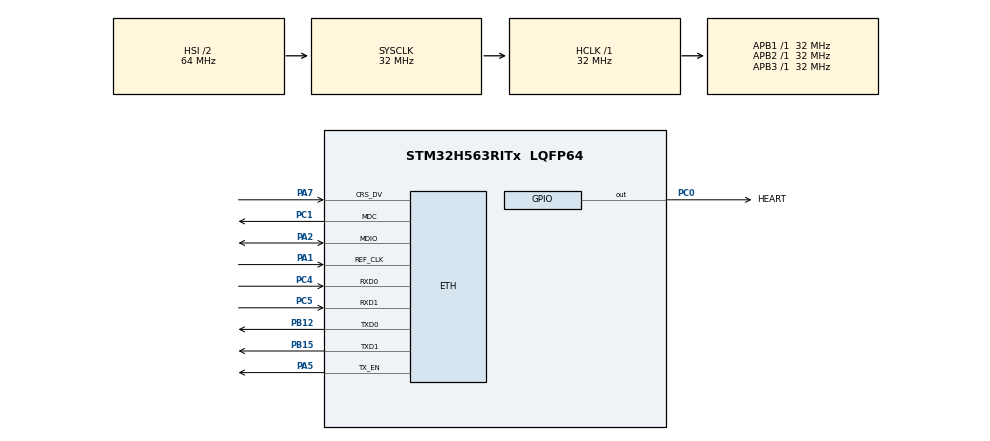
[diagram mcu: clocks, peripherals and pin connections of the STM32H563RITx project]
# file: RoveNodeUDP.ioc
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CORTEX_M33_NS.Number-Cortex_Memory_Protection_Unit_Region0_OTP_RO_AREAS_Settings=MPU_REGION_NUMBER0
CORTEX_M33_NS.default_mode_Activation=1
CORTEX_M33_NS.userName=CORTEX_M33
ETH.MediaInterface=HAL_ETH_RMII_MODE
Mcu.Family=STM32H5
Mcu.Name=STM32H563RITx
Mcu.Package=LQFP64
NVIC.ETH_IRQn=true\:0\:0\:false\:false\:true\:true\:true\:true
NVIC.PriorityGroup=NVIC_PRIORITYGROUP_4
PA1.Mode=RMII
PA1.Signal=ETH_REF_CLK
PA13(JTMS/SWDIO).Mode=Serial_Wire
PA13(JTMS/SWDIO).Signal=DEBUG_JTMS-SWDIO
PA14(JTCK/SWCLK).Mode=Serial_Wire
PA14(JTCK/SWCLK).Signal=DEBUG_JTCK-SWCLK
PA2.Mode=RMII
PA2.Signal=ETH_MDIO
PA5.Mode=RMII
PA5.Signal=ETH_TX_EN
PA7.Mode=RMII
PA7.Signal=ETH_CRS_DV
PB12.Mode=RMII
PB12.Signal=ETH_TXD0
PB15.Mode=RMII
PB15.Signal=ETH_TXD1
PC0.GPIO_Label=HEART
PC0.Signal=GPIO_Output
PC1.Mode=RMII
PC1.Signal=ETH_MDC
PC4.Mode=RMII
PC4.Signal=ETH_RXD0
PC5.Mode=RMII
PC5.Signal=ETH_RXD1
ProjectManager.HeapSize=0x200
ProjectManager.StackSize=0x400
ProjectManager.TargetToolchain=STM32CubeIDE
RCC.ADCFreq_Value=32000000
RCC.AHBFreq_Value=32000000
RCC.APB1Freq_Value=32000000
RCC.APB1TimFreq_Value=32000000
RCC.APB2Freq_Value=32000000
RCC.APB2TimFreq_Value=32000000
RCC.APB3Freq_Value=32000000
RCC.CSI_VALUE=4000000
RCC.CortexFreq_Value=32000000
RCC.EPOD_VALUE=4000000
RCC.HCLKFreq_Value=32000000
RCC.HSE_VALUE=25000000
RCC.HSI48_VALUE=48000000
RCC.HSI_VALUE=64000000
RCC.LSE_VALUE=32768
RCC.LSIRC_VALUE=32000
RCC.PLLFRACN=0
RCC.PLLN=32
RCC.SYSCLKFreq_VALUE=32000000
RCC.USBFreq_Value=48000000
RCC.VCOOutputFreq_Value=128000000
VP_BOOTPATH_VS_BOOTPATH.Mode=BP_Activate
VP_CORTEX_M33_NS_VS_Hclk.Mode=Hclk_Mode
VP_ICACHE_VS_ICACHE.Mode=DirectMappedCache
VP_MEMORYMAP_VS_MEMORYMAP.Mode=CurAppReg
VP_PWR_VS_LPOM.Mode=PowerOptimisation
VP_PWR_VS_SECSignals.Mode=Security/Privilege
board=custom

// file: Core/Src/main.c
/* USER CODE BEGIN Header */
/**
  ******************************************************************************
  * @file           : main.c
  * @brief          : Main program body
  ******************************************************************************
  * @attention
  *
  * Copyright (c) 2026 STMicroelectronics.
  * All rights reserved.
  *
  * This software is licensed under terms that can be found in the LICENSE file
  * in the root directory of this software component.
  * If no LICENSE file comes with this software, it is provided AS-IS.
  *
  ******************************************************************************
  */
/* USER CODE END Header */
#include "main.h"
#include "string.h"

ETH_TxPacketConfigTypeDef TxConfig;
ETH_DMADescTypeDef  DMARxDscrTab[ETH_RX_DESC_CNT]; /* Ethernet Rx DMA Descriptors */
ETH_DMADescTypeDef  DMATxDscrTab[ETH_TX_DESC_CNT]; /* Ethernet Tx DMA Descriptors */

ETH_HandleTypeDef heth;

/* USER CODE BEGIN PV */
struct netif gnetif;

void udp_receive_callback(void *arg, struct udp_pcb *upcb, struct pbuf *p, const ip_addr_t *addr, u16_t port);
static void udpClient_send(const char *message);

struct udp_pcb *upcb;
char buffer[100];
/* USER CODE END PV */

void SystemClock_Config(void);
static void MPU_Config(void);
static void MX_GPIO_Init(void);
static void MX_ETH_Init(void);
static void MX_ICACHE_Init(void);

/* USER CODE BEGIN 0 */
static void udpClient_send(const char *message)
{
    struct pbuf *txBuf;
    int len = strlen(message);

    /* Allocate pbuf from pool */
    txBuf = pbuf_alloc(PBUF_TRANSPORT, len, PBUF_RAM);

    if (txBuf != NULL)
    {
        /* Copy data to pbuf */
        pbuf_take(txBuf, message, len);

        /* Send UDP data */
        udp_send(upcb, txBuf);

        /* Free pbuf */
        pbuf_free(txBuf);
    }
}

void udp_receive_callback(void *arg, struct udp_pcb *upcb, struct pbuf *p, const ip_addr_t *addr, u16_t port)
{
	if (p != NULL)
	    {
	        /* Safely copy data into 'buffer' up to its maximum size (minus 1 for null terminator) */
	        uint16_t copy_len = (p->tot_len < (sizeof(buffer) - 1)) ? p->tot_len : (sizeof(buffer) - 1);
	        pbuf_copy_partial(p, buffer, copy_len, 0);
	        buffer[copy_len] = '\0'; // Ensure null termination

	        HAL_GPIO_TogglePin(GPIOB, GPIO_PIN_0);

	        /* Free receive pbuf */
	        pbuf_free(p);
	    }
}
/* USER CODE END 0 */

int main(void)
{

  /* MCU Configuration--------------------------------------------------------*/

  /* MPU Configuration--------------------------------------------------------*/
  MPU_Config();

  /* Reset of all peripherals, Initializes the Flash interface and the Systick. */
  HAL_Init();

  /* Configure the system clock */
  SystemClock_Config();

  /* Initialize all configured peripherals */
  MX_GPIO_Init();
  MX_ETH_Init();
  MX_ICACHE_Init();
  /* USER CODE BEGIN 2 */
  HAL_ETH_Start(&heth);
  //SCB_DisableDCache();
  //SCB_DisableICache();

  err_t err;

  /* 1. Create a new UDP control block  */
  upcb = udp_new();

  /* Bind the block to module's IP and port */
  ip_addr_t myIPaddr;
  IP_ADDR4(&myIPaddr, 192, 168, 8, 200);
  udp_bind(upcb, &myIPaddr, 1100);

  /* Configure destination IP address and port */
  ip_addr_t DestIPaddr;
  IP_ADDR4(&DestIPaddr, 192, 168, 8, 108);
  err = udp_connect(upcb, &DestIPaddr, 1234);

  HAL_GPIO_WritePin(GPIOB, GPIO_PIN_0, 1);
  if (err == ERR_OK)
  {
	  /* 2. Send "Hello World" message to server */
	  udpClient_send("Hello World");

	  /* 3. Set a receive callback for the upcb */
	  udp_recv(upcb, udp_receive_callback, NULL);
  }

  /* USER CODE END 2 */

  /* Infinite loop */
  /* USER CODE BEGIN WHILE */
  while (1)
  {
	ethernetif_input(&gnetif);
	sys_check_timeouts();

	//udpClient_send("Hello World");
    /* USER CODE END WHILE */

  }
}

void SystemClock_Config(void)
{
  RCC_OscInitTypeDef RCC_OscInitStruct = {0};
  RCC_ClkInitTypeDef RCC_ClkInitStruct = {0};

  /** Configure the main internal regulator output voltage
  */
  __HAL_PWR_VOLTAGESCALING_CONFIG(PWR_REGULATOR_VOLTAGE_SCALE3);

  while(!__HAL_PWR_GET_FLAG(PWR_FLAG_VOSRDY)) {}

  /** Initializes the RCC Oscillators according to the specified parameters
  * in the RCC_OscInitTypeDef structure.
  */
  RCC_OscInitStruct.OscillatorType = RCC_OSCILLATORTYPE_HSI|RCC_OSCILLATORTYPE_CSI;
  RCC_OscInitStruct.HSIState = RCC_HSI_ON;
  RCC_OscInitStruct.HSIDiv = RCC_HSI_DIV2;
  RCC_OscInitStruct.HSICalibrationValue = RCC_HSICALIBRATION_DEFAULT;
  RCC_OscInitStruct.CSIState = RCC_CSI_ON;
  RCC_OscInitStruct.CSICalibrationValue = RCC_CSICALIBRATION_DEFAULT;
  RCC_OscInitStruct.PLL.PLLState = RCC_PLL_ON;
  RCC_OscInitStruct.PLL.PLLSource = RCC_PLL1_SOURCE_CSI;
  RCC_OscInitStruct.PLL.PLLM = 1;
  RCC_OscInitStruct.PLL.PLLN = 129;
  RCC_OscInitStruct.PLL.PLLP = 2;
  RCC_OscInitStruct.PLL.PLLQ = 2;
  RCC_OscInitStruct.PLL.PLLR = 2;
  RCC_OscInitStruct.PLL.PLLRGE = RCC_PLL1_VCIRANGE_2;
  RCC_OscInitStruct.PLL.PLLVCOSEL = RCC_PLL1_VCORANGE_WIDE;
  RCC_OscInitStruct.PLL.PLLFRACN = 0;
  if (HAL_RCC_OscConfig(&RCC_OscInitStruct) != HAL_OK)
  {
    Error_Handler();
  }

  /** Initializes the CPU, AHB and APB buses clocks
  */
  RCC_ClkInitStruct.ClockType = RCC_CLOCKTYPE_HCLK|RCC_CLOCKTYPE_SYSCLK
                              |RCC_CLOCKTYPE_PCLK1|RCC_CLOCKTYPE_PCLK2
                              |RCC_CLOCKTYPE_PCLK3;
  RCC_ClkInitStruct.SYSCLKSource = RCC_SYSCLKSOURCE_HSI;
  RCC_ClkInitStruct.AHBCLKDivider = RCC_SYSCLK_DIV1;
  RCC_ClkInitStruct.APB1CLKDivider = RCC_HCLK_DIV1;
  RCC_ClkInitStruct.APB2CLKDivider = RCC_HCLK_DIV1;
  RCC_ClkInitStruct.APB3CLKDivider = RCC_HCLK_DIV1;

  if (HAL_RCC_ClockConfig(&RCC_ClkInitStruct, FLASH_LATENCY_1) != HAL_OK)
  {
    Error_Handler();
  }

  /** Configure the programming delay
  */
  __HAL_FLASH_SET_PROGRAM_DELAY(FLASH_PROGRAMMING_DELAY_0);
}

static void MX_ETH_Init(void)
{

   static uint8_t MACAddr[6];

  heth.Instance = ETH;
  MACAddr[0] = 0x00;
  MACAddr[1] = 0x80;
  MACAddr[2] = 0xE1;
  MACAddr[3] = 0x00;
  MACAddr[4] = 0x00;
  MACAddr[5] = 0x00;
  heth.Init.MACAddr = &MACAddr[0];
  heth.Init.MediaInterface = HAL_ETH_RMII_MODE;
  heth.Init.TxDesc = DMATxDscrTab;
  heth.Init.RxDesc = DMARxDscrTab;
  heth.Init.RxBuffLen = 1524;

  if (HAL_ETH_Init(&heth) != HAL_OK)
  {
    Error_Handler();
  }

  memset(&TxConfig, 0 , sizeof(ETH_TxPacketConfigTypeDef));
  TxConfig.Attributes = ETH_TX_PACKETS_FEATURES_CSUM | ETH_TX_PACKETS_FEATURES_CRCPAD;
  TxConfig.ChecksumCtrl = ETH_CHECKSUM_IPHDR_PAYLOAD_INSERT_PHDR_CALC;
  TxConfig.CRCPadCtrl = ETH_CRC_PAD_INSERT;

}

static void MX_ICACHE_Init(void)
{

  /** Enable instruction cache in 1-way (direct mapped cache)
  */
  if (HAL_ICACHE_ConfigAssociativityMode(ICACHE_1WAY) != HAL_OK)
  {
    Error_Handler();
  }
  if (HAL_ICACHE_Enable() != HAL_OK)
  {
    Error_Handler();
  }

}

static void MX_GPIO_Init(void)
{
  GPIO_InitTypeDef GPIO_InitStruct = {0};

  /* GPIO Ports Clock Enable */
  __HAL_RCC_GPIOC_CLK_ENABLE();
  __HAL_RCC_GPIOA_CLK_ENABLE();
  __HAL_RCC_GPIOB_CLK_ENABLE();

  /*Configure GPIO pin Output Level */
  HAL_GPIO_WritePin(GPIOB, GPIO_PIN_0, GPIO_PIN_RESET);

  /*Configure GPIO pin : PB0 */
  GPIO_InitStruct.Pin = GPIO_PIN_0;
  GPIO_InitStruct.Mode = GPIO_MODE_OUTPUT_PP;
  GPIO_InitStruct.Pull = GPIO_NOPULL;
  GPIO_InitStruct.Speed = GPIO_SPEED_FREQ_LOW;
  HAL_GPIO_Init(GPIOB, &GPIO_InitStruct);

}

 /* MPU Configuration */

void MPU_Config(void)
{
  MPU_Region_InitTypeDef MPU_InitStruct = {0};
  MPU_Attributes_InitTypeDef MPU_AttributesInit = {0};

  /* Disables the MPU */
  HAL_MPU_Disable();

  /** Initializes and configures the Region 0 and the memory to be protected
  */
  MPU_InitStruct.Enable = MPU_REGION_ENABLE;
  MPU_InitStruct.Number = MPU_REGION_NUMBER0;
  MPU_InitStruct.BaseAddress = 0x08FFF000;
  MPU_InitStruct.LimitAddress = 0x08FFFFFF;
  MPU_InitStruct.AttributesIndex = MPU_ATTRIBUTES_NUMBER0;
  MPU_InitStruct.AccessPermission = MPU_REGION_ALL_RO;
  MPU_InitStruct.DisableExec = MPU_INSTRUCTION_ACCESS_DISABLE;
  MPU_InitStruct.IsShareable = MPU_ACCESS_NOT_SHAREABLE;

  HAL_MPU_ConfigRegion(&MPU_InitStruct);

  /** Initializes and configures the Attribute 0 and the memory to be protected
  */
  MPU_AttributesInit.Number = MPU_ATTRIBUTES_NUMBER0;
  MPU_AttributesInit.Attributes = INNER_OUTER(MPU_NOT_CACHEABLE);

  HAL_MPU_ConfigMemoryAttributes(&MPU_AttributesInit);
  /* Enables the MPU */
  HAL_MPU_Enable(MPU_PRIVILEGED_DEFAULT);

}

void Error_Handler(void)
{
  __disable_irq();
  while (1)
  {
  }
}
